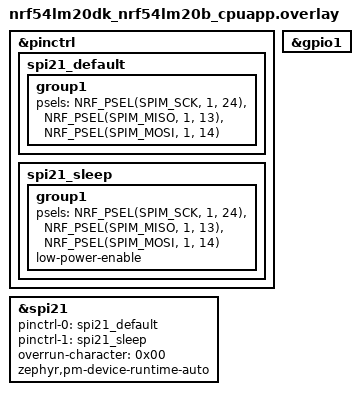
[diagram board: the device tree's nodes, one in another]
/*
 * Copyright (c) 2026 Nordic Semiconductor ASA
 *
 * SPDX-License-Identifier: Apache-2.0
 */

/* Test requires following loopback:
 * P1.13 - P1.14
 */

&pinctrl {
	spi21_default: spi21_default {
		group1 {
			psels = <NRF_PSEL(SPIM_SCK, 1, 24)>,
				<NRF_PSEL(SPIM_MISO, 1, 13)>,
				<NRF_PSEL(SPIM_MOSI, 1, 14)>;
		};
	};

	spi21_sleep: spi21_sleep {
		group1 {
			psels = <NRF_PSEL(SPIM_SCK, 1, 24)>,
				<NRF_PSEL(SPIM_MISO, 1, 13)>,
				<NRF_PSEL(SPIM_MOSI, 1, 14)>;
			low-power-enable;
		};
	};
};

#define SPI_LOOPBACK_SLOW_HZ DT_FREQ_M(2)
#define SPI_LOOPBACK_FAST_HZ DT_FREQ_M(4)

spi_loopback: &spi21 {
	status = "okay";
	pinctrl-0 = <&spi21_default>;
	pinctrl-1 = <&spi21_sleep>;
	pinctrl-names = "default", "sleep";
	overrun-character = <0x00>;
	zephyr,pm-device-runtime-auto;
};

&gpio1 {
	status = "okay";
};

#include "../spi-loopback.dtsi"
